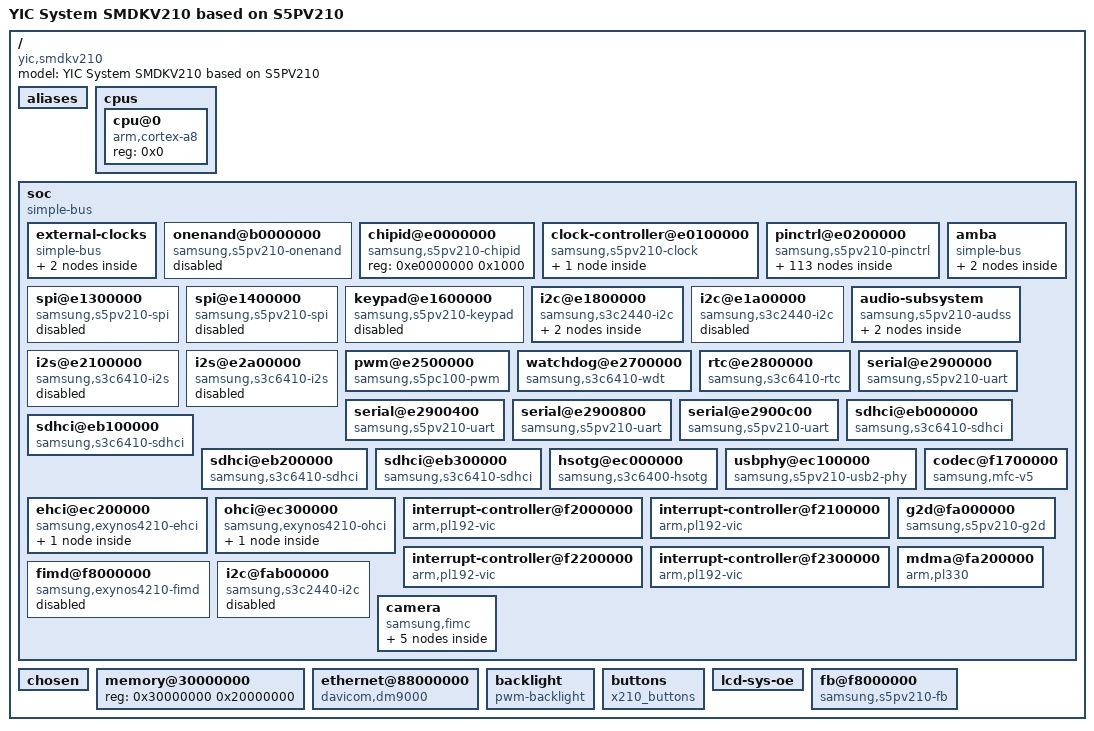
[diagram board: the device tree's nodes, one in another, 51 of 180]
/dts-v1/;

/ {
	#address-cells = <0x1>;
	#size-cells = <0x1>;
	model = "YIC System SMDKV210 based on S5PV210";
	compatible = "yic,smdkv210", "samsung,s5pv210";

	aliases {
		csis0 = "/soc/camera/csis@fa600000";
		fimc0 = "/soc/camera/fimc@fb200000";
		fimc1 = "/soc/camera/fimc@fb300000";
		fimc2 = "/soc/camera/fimc@fb400000";
		i2c0 = "/soc/i2c@e1800000";
		i2c1 = "/soc/i2c@fab00000";
		i2c2 = "/soc/i2c@e1a00000";
		i2s0 = "/soc/audio-subsystem/i2s@eee30000";
		i2s1 = "/soc/i2s@e2100000";
		i2s2 = "/soc/i2s@e2a00000";
		pinctrl0 = "/soc/pinctrl@e0200000";
		spi0 = "/soc/spi@e1300000";
		spi1 = "/soc/spi@e1400000";
	};

	cpus {
		#address-cells = <0x1>;
		#size-cells = <0x0>;

		cpu@0 {
			device_type = "cpu";
			compatible = "arm,cortex-a8";
			reg = <0x0>;
		};
	};

	soc {
		compatible = "simple-bus";
		#address-cells = <0x1>;
		#size-cells = <0x1>;
		ranges;

		external-clocks {
			compatible = "simple-bus";
			#address-cells = <0x1>;
			#size-cells = <0x0>;

			oscillator@0 {
				compatible = "fixed-clock";
				reg = <0x0>;
				clock-frequency = <0x0>;
				clock-output-names = "xxti";
				#clock-cells = <0x0>;
				phandle = <0x3>;
			};

			oscillator@1 {
				compatible = "fixed-clock";
				reg = <0x1>;
				clock-frequency = <0x16e3600>;
				clock-output-names = "xusbxti";
				#clock-cells = <0x0>;
				phandle = <0x4>;
			};
		};

		onenand@b0000000 {
			compatible = "samsung,s5pv210-onenand";
			reg = <0xb0600000 0x2000 0xb0000000 0x20000 0xb0040000 0x20000>;
			interrupt-parent = <0x1>;
			interrupts = <0x1f>;
			clocks = <0x2 0x68 0x2 0x50>;
			clock-names = "bus", "onenand";
			#address-cells = <0x1>;
			#size-cells = <0x1>;
			status = "disabled";
		};

		chipid@e0000000 {
			compatible = "samsung,s5pv210-chipid";
			reg = <0xe0000000 0x1000>;
		};

		clock-controller@e0100000 {
			compatible = "samsung,s5pv210-clock", "simple-bus";
			reg = <0xe0100000 0x10000>;
			clock-names = "xxti", "xusbxti";
			clocks = <0x3 0x4>;
			#clock-cells = <0x1>;
			#address-cells = <0x1>;
			#size-cells = <0x1>;
			ranges;
			phandle = <0x2>;

			syscon@e0108000 {
				compatible = "samsung-s5pv210-pmu", "syscon";
				reg = <0xe0108000 0x8000>;
				phandle = <0x27>;
			};
		};

		pinctrl@e0200000 {
			compatible = "samsung,s5pv210-pinctrl";
			reg = <0xe0200000 0x1000>;
			interrupt-parent = <0x5>;
			interrupts = <0x1e>;

			wakeup-interrupt-controller {
				compatible = "samsung,exynos4210-wakeup-eint";
				interrupts = <0x10>;
				interrupt-parent = <0x5>;
			};

			gpa0 {
				gpio-controller;
				#gpio-cells = <0x2>;
				interrupt-controller;
				#interrupt-cells = <0x2>;
			};

			gpa1 {
				gpio-controller;
				#gpio-cells = <0x2>;
				interrupt-controller;
				#interrupt-cells = <0x2>;
			};

			gpb {
				gpio-controller;
				#gpio-cells = <0x2>;
				interrupt-controller;
				#interrupt-cells = <0x2>;
			};

			gpc0 {
				gpio-controller;
				#gpio-cells = <0x2>;
				interrupt-controller;
				#interrupt-cells = <0x2>;
			};

			gpc1 {
				gpio-controller;
				#gpio-cells = <0x2>;
				interrupt-controller;
				#interrupt-cells = <0x2>;
			};

			gpd0 {
				gpio-controller;
				#gpio-cells = <0x2>;
				interrupt-controller;
				#interrupt-cells = <0x2>;
			};

			gpd1 {
				gpio-controller;
				#gpio-cells = <0x2>;
				interrupt-controller;
				#interrupt-cells = <0x2>;
			};

			gpe0 {
				gpio-controller;
				#gpio-cells = <0x2>;
				interrupt-controller;
				#interrupt-cells = <0x2>;
			};

			gpe1 {
				gpio-controller;
				#gpio-cells = <0x2>;
				interrupt-controller;
				#interrupt-cells = <0x2>;
			};

			gpf0 {
				gpio-controller;
				#gpio-cells = <0x2>;
				interrupt-controller;
				#interrupt-cells = <0x2>;
			};

			gpf1 {
				gpio-controller;
				#gpio-cells = <0x2>;
				interrupt-controller;
				#interrupt-cells = <0x2>;
			};

			gpf2 {
				gpio-controller;
				#gpio-cells = <0x2>;
				interrupt-controller;
				#interrupt-cells = <0x2>;
			};

			gpf3 {
				gpio-controller;
				#gpio-cells = <0x2>;
				interrupt-controller;
				#interrupt-cells = <0x2>;
			};

			gpg0 {
				gpio-controller;
				#gpio-cells = <0x2>;
				interrupt-controller;
				#interrupt-cells = <0x2>;
			};

			gpg1 {
				gpio-controller;
				#gpio-cells = <0x2>;
				interrupt-controller;
				#interrupt-cells = <0x2>;
			};

			gpg2 {
				gpio-controller;
				#gpio-cells = <0x2>;
				interrupt-controller;
				#interrupt-cells = <0x2>;
			};

			gpg3 {
				gpio-controller;
				#gpio-cells = <0x2>;
				interrupt-controller;
				#interrupt-cells = <0x2>;
			};

			gpj0 {
				gpio-controller;
				#gpio-cells = <0x2>;
				interrupt-controller;
				#interrupt-cells = <0x2>;
			};

			gpj1 {
				gpio-controller;
				#gpio-cells = <0x2>;
				interrupt-controller;
				#interrupt-cells = <0x2>;
			};

			gpj2 {
				gpio-controller;
				#gpio-cells = <0x2>;
				interrupt-controller;
				#interrupt-cells = <0x2>;
			};

			gpj3 {
				gpio-controller;
				#gpio-cells = <0x2>;
				interrupt-controller;
				#interrupt-cells = <0x2>;
			};

			gpj4 {
				gpio-controller;
				#gpio-cells = <0x2>;
				interrupt-controller;
				#interrupt-cells = <0x2>;
			};

			gpgi {
				gpio-controller;
				#gpio-cells = <0x2>;
			};

			mp01 {
				gpio-controller;
				#gpio-cells = <0x2>;
			};

			mp02 {
				gpio-controller;
				#gpio-cells = <0x2>;
			};

			mp03 {
				gpio-controller;
				#gpio-cells = <0x2>;
			};

			mp04 {
				gpio-controller;
				#gpio-cells = <0x2>;
			};

			mp05 {
				gpio-controller;
				#gpio-cells = <0x2>;
			};

			mp06 {
				gpio-controller;
				#gpio-cells = <0x2>;
			};

			mp07 {
				gpio-controller;
				#gpio-cells = <0x2>;
			};

			gph0 {
				gpio-controller;
				interrupt-controller;
				interrupt-parent = <0x5>;
				interrupts = <0x0 0x1 0x2 0x3 0x4 0x5 0x6 0x7>;
				#gpio-cells = <0x2>;
				#interrupt-cells = <0x2>;
			};

			gph1 {
				gpio-controller;
				interrupt-controller;
				interrupt-parent = <0x5>;
				interrupts = <0x8 0x9 0xa 0xb 0xc 0xd 0xe 0xf>;
				#gpio-cells = <0x2>;
				#interrupt-cells = <0x2>;
				phandle = <0x29>;
			};

			gph2 {
				gpio-controller;
				#gpio-cells = <0x2>;
				interrupt-controller;
				#interrupt-cells = <0x2>;
				phandle = <0x2c>;
			};

			gph3 {
				gpio-controller;
				#gpio-cells = <0x2>;
				#interrupt-cells = <0x2>;
			};

			uart0-data {
				samsung,pins = "gpa0-0", "gpa0-1";
				samsung,pin-function = <0x2>;
				samsung,pin-pud = <0x0>;
				samsung,pin-drv = <0x0>;
			};

			uart0-fctl {
				samsung,pins = "gpa0-2", "gpa0-3";
				samsung,pin-function = <0x2>;
				samsung,pin-pud = <0x0>;
				samsung,pin-drv = <0x0>;
			};

			uart1-data {
				samsung,pins = "gpa0-4", "gpa0-5";
				samsung,pin-function = <0x2>;
				samsung,pin-pud = <0x0>;
				samsung,pin-drv = <0x0>;
			};

			uart1-fctl {
				samsung,pins = "gpa0-6", "gpa0-7";
				samsung,pin-function = <0x2>;
				samsung,pin-pud = <0x0>;
				samsung,pin-drv = <0x0>;
			};

			uart2-data {
				samsung,pins = "gpa1-0", "gpa1-1";
				samsung,pin-function = <0x2>;
				samsung,pin-pud = <0x0>;
				samsung,pin-drv = <0x0>;
			};

			uart2-fctl {
				samsung,pins = "gpa1-2", "gpa1-3";
				samsung,pin-function = <0x3>;
				samsung,pin-pud = <0x0>;
				samsung,pin-drv = <0x0>;
			};

			uart3-data {
				samsung,pins = "gpa1-2", "gpa1-3";
				samsung,pin-function = <0x2>;
				samsung,pin-pud = <0x0>;
				samsung,pin-drv = <0x0>;
			};

			uart-audio {
				samsung,pins = "gpa1-2", "gpa1-3";
				samsung,pin-function = <0x4>;
				samsung,pin-pud = <0x0>;
				samsung,pin-drv = <0x0>;
			};

			spi0-bus {
				samsung,pins = "gpb-0", "gpb-2", "gpb-3";
				samsung,pin-function = <0x2>;
				samsung,pin-pud = <0x2>;
				samsung,pin-drv = <0x0>;
				phandle = <0x7>;
			};

			spi1-bus {
				samsung,pins = "gpb-4", "gpb-6", "gpb-7";
				samsung,pin-function = <0x2>;
				samsung,pin-pud = <0x2>;
				samsung,pin-drv = <0x0>;
				phandle = <0x9>;
			};

			i2s0-bus {
				samsung,pins = "gpi-0", "gpi-1", "gpi-2", "gpi-3", "gpi-4", "gpi-5", "gpi-6";
				samsung,pin-function = <0x2>;
				samsung,pin-pud = <0x0>;
				samsung,pin-drv = <0x0>;
				phandle = <0xe>;
			};

			i2s1-bus {
				samsung,pins = "gpc0-0", "gpc0-1", "gpc0-2", "gpc0-3", "gpc0-4";
				samsung,pin-function = <0x2>;
				samsung,pin-pud = <0x0>;
				samsung,pin-drv = <0x0>;
				phandle = <0xf>;
			};

			i2s2-bus {
				samsung,pins = "gpc1-0", "gpc1-1", "gpc1-2", "gpc1-3", "gpc1-4";
				samsung,pin-function = <0x2>;
				samsung,pin-pud = <0x0>;
				samsung,pin-drv = <0x0>;
				phandle = <0x10>;
			};

			pcm1-bus {
				samsung,pins = "gpc0-0", "gpc0-1", "gpc0-2", "gpc0-3", "gpc0-4";
				samsung,pin-function = <0x3>;
				samsung,pin-pud = <0x0>;
				samsung,pin-drv = <0x0>;
			};

			ac97-bus {
				samsung,pins = "gpc0-0", "gpc0-1", "gpc0-2", "gpc0-3", "gpc0-4";
				samsung,pin-function = <0x4>;
				samsung,pin-pud = <0x0>;
				samsung,pin-drv = <0x0>;
			};

			pcm2-bus {
				samsung,pins = "gpc1-0", "gpc1-1", "gpc1-2", "gpc1-3", "gpc1-4";
				samsung,pin-function = <0x3>;
				samsung,pin-pud = <0x0>;
				samsung,pin-drv = <0x0>;
			};

			spdif-bus {
				samsung,pins = "gpc1-0", "gpc1-1";
				samsung,pin-function = <0x4>;
				samsung,pin-pud = <0x0>;
				samsung,pin-drv = <0x0>;
			};

			spi2-bus {
				samsung,pins = "gpc1-1", "gpc1-2", "gpc1-3", "gpc1-4";
				samsung,pin-function = <0x5>;
				samsung,pin-pud = <0x2>;
				samsung,pin-drv = <0x0>;
			};

			i2c0-bus {
				samsung,pins = "gpd1-0", "gpd1-1";
				samsung,pin-function = <0x2>;
				samsung,pin-pud = <0x2>;
				samsung,pin-drv = <0x0>;
				phandle = <0xb>;
			};

			i2c1-bus {
				samsung,pins = "gpd1-2", "gpd1-3";
				samsung,pin-function = <0x2>;
				samsung,pin-pud = <0x2>;
				samsung,pin-drv = <0x0>;
				phandle = <0x28>;
			};

			i2c2-bus {
				samsung,pins = "gpd1-4", "gpd1-5";
				samsung,pin-function = <0x2>;
				samsung,pin-pud = <0x2>;
				samsung,pin-drv = <0x0>;
				phandle = <0xc>;
			};

			pwm0-out {
				samsung,pins = "gpd0-0";
				samsung,pin-function = <0x2>;
				samsung,pin-pud = <0x0>;
				samsung,pin-drv = <0x0>;
			};

			pwm1-out {
				samsung,pins = "gpd0-1";
				samsung,pin-function = <0x2>;
				samsung,pin-pud = <0x0>;
				samsung,pin-drv = <0x0>;
			};

			pwm2-out {
				samsung,pins = "gpd0-2";
				samsung,pin-function = <0x2>;
				samsung,pin-pud = <0x0>;
				samsung,pin-drv = <0x0>;
			};

			pwm3-out {
				samsung,pins = "gpd0-3";
				samsung,pin-function = <0x2>;
				samsung,pin-pud = <0x0>;
				samsung,pin-drv = <0x0>;
				phandle = <0x2b>;
			};

			keypad-row-0 {
				samsung,pins = "gph3-0";
				samsung,pin-function = <0x3>;
				samsung,pin-pud = <0x0>;
				samsung,pin-drv = <0x0>;
			};

			keypad-row-1 {
				samsung,pins = "gph3-1";
				samsung,pin-function = <0x3>;
				samsung,pin-pud = <0x0>;
				samsung,pin-drv = <0x0>;
			};

			keypad-row-2 {
				samsung,pins = "gph3-2";
				samsung,pin-function = <0x3>;
				samsung,pin-pud = <0x0>;
				samsung,pin-drv = <0x0>;
			};

			keypad-row-3 {
				samsung,pins = "gph3-3";
				samsung,pin-function = <0x3>;
				samsung,pin-pud = <0x0>;
				samsung,pin-drv = <0x0>;
			};

			keypad-row-4 {
				samsung,pins = "gph3-4";
				samsung,pin-function = <0x3>;
				samsung,pin-pud = <0x0>;
				samsung,pin-drv = <0x0>;
			};

			keypad-row-5 {
				samsung,pins = "gph3-5";
				samsung,pin-function = <0x3>;
				samsung,pin-pud = <0x0>;
				samsung,pin-drv = <0x0>;
			};

			keypad-row-6 {
				samsung,pins = "gph3-6";
				samsung,pin-function = <0x3>;
				samsung,pin-pud = <0x0>;
				samsung,pin-drv = <0x0>;
			};

			keypad-row-7 {
				samsung,pins = "gph3-7";
				samsung,pin-function = <0x3>;
				samsung,pin-pud = <0x0>;
				samsung,pin-drv = <0x0>;
			};

			keypad-col-0 {
				samsung,pins = "gph2-0";
				samsung,pin-function = <0x3>;
				samsung,pin-pud = <0x0>;
				samsung,pin-drv = <0x0>;
			};

			keypad-col-1 {
				samsung,pins = "gph2-1";
				samsung,pin-function = <0x3>;
				samsung,pin-pud = <0x0>;
				samsung,pin-drv = <0x0>;
			};

			keypad-col-2 {
				samsung,pins = "gph2-2";
				samsung,pin-function = <0x3>;
				samsung,pin-pud = <0x0>;
				samsung,pin-drv = <0x0>;
			};

			keypad-col-3 {
				samsung,pins = "gph2-3";
				samsung,pin-function = <0x3>;
				samsung,pin-pud = <0x0>;
				samsung,pin-drv = <0x0>;
			};

			keypad-col-4 {
				samsung,pins = "gph2-4";
				samsung,pin-function = <0x3>;
				samsung,pin-pud = <0x0>;
				samsung,pin-drv = <0x0>;
			};

			keypad-col-5 {
				samsung,pins = "gph2-5";
				samsung,pin-function = <0x3>;
				samsung,pin-pud = <0x0>;
				samsung,pin-drv = <0x0>;
			};

			keypad-col-6 {
				samsung,pins = "gph2-6";
				samsung,pin-function = <0x3>;
				samsung,pin-pud = <0x0>;
				samsung,pin-drv = <0x0>;
			};

			keypad-col-7 {
				samsung,pins = "gph2-7";
				samsung,pin-function = <0x3>;
				samsung,pin-pud = <0x0>;
				samsung,pin-drv = <0x0>;
			};

			sd0-clk {
				samsung,pins = "gpg0-0";
				samsung,pin-function = <0x2>;
				samsung,pin-pud = <0x0>;
				samsung,pin-drv = <0x3>;
				phandle = <0x11>;
			};

			sd0-cmd {
				samsung,pins = "gpg0-1";
				samsung,pin-function = <0x2>;
				samsung,pin-pud = <0x0>;
				samsung,pin-drv = <0x3>;
				phandle = <0x12>;
			};

			sd0-cd {
				samsung,pins = "gpg0-2";
				samsung,pin-function = <0x2>;
				samsung,pin-pud = <0x2>;
				samsung,pin-drv = <0x3>;
				phandle = <0x13>;
			};

			sd0-bus-width1 {
				samsung,pins = "gpg0-3";
				samsung,pin-function = <0x2>;
				samsung,pin-pud = <0x2>;
				samsung,pin-drv = <0x3>;
				phandle = <0x14>;
			};

			sd0-bus-width4 {
				samsung,pins = "gpg0-3", "gpg0-4", "gpg0-5", "gpg0-6";
				samsung,pin-function = <0x2>;
				samsung,pin-pud = <0x2>;
				samsung,pin-drv = <0x3>;
				phandle = <0x15>;
			};

			sd0-bus-width8 {
				samsung,pins = "gpg1-3", "gpg1-4", "gpg1-5", "gpg1-6";
				samsung,pin-function = <0x3>;
				samsung,pin-pud = <0x2>;
				samsung,pin-drv = <0x3>;
			};

			sd1-clk {
				samsung,pins = "gpg1-0";
				samsung,pin-function = <0x2>;
				samsung,pin-pud = <0x0>;
				samsung,pin-drv = <0x3>;
				phandle = <0x16>;
			};

			sd1-cmd {
				samsung,pins = "gpg1-1";
				samsung,pin-function = <0x2>;
				samsung,pin-pud = <0x0>;
				samsung,pin-drv = <0x3>;
				phandle = <0x17>;
			};

			sd1-cd {
				samsung,pins = "gpg1-2";
				samsung,pin-function = <0x2>;
				samsung,pin-pud = <0x2>;
				samsung,pin-drv = <0x3>;
				phandle = <0x18>;
			};

			sd1-bus-width1 {
				samsung,pins = "gpg1-3";
				samsung,pin-function = <0x2>;
				samsung,pin-pud = <0x2>;
				samsung,pin-drv = <0x3>;
				phandle = <0x19>;
			};

			sd1-bus-width4 {
				samsung,pins = "gpg1-3", "gpg1-4", "gpg1-5", "gpg1-6";
				samsung,pin-function = <0x2>;
				samsung,pin-pud = <0x2>;
				samsung,pin-drv = <0x3>;
				phandle = <0x1a>;
			};

			sd2-clk {
				samsung,pins = "gpg2-0";
				samsung,pin-function = <0x2>;
				samsung,pin-pud = <0x0>;
				samsung,pin-drv = <0x3>;
				phandle = <0x1b>;
			};

			sd2-cmd {
				samsung,pins = "gpg2-1";
				samsung,pin-function = <0x2>;
				samsung,pin-pud = <0x0>;
				samsung,pin-drv = <0x3>;
				phandle = <0x1c>;
			};

			sd2-cd {
				samsung,pins = "gpg2-2";
				samsung,pin-function = <0x2>;
				samsung,pin-pud = <0x2>;
				samsung,pin-drv = <0x3>;
				phandle = <0x1d>;
			};

			sd2-bus-width1 {
				samsung,pins = "gpg2-3";
				samsung,pin-function = <0x2>;
				samsung,pin-pud = <0x2>;
				samsung,pin-drv = <0x3>;
				phandle = <0x1e>;
			};

			sd2-bus-width4 {
				samsung,pins = "gpg2-3", "gpg2-4", "gpg2-5", "gpg2-6";
				samsung,pin-function = <0x2>;
				samsung,pin-pud = <0x2>;
				samsung,pin-drv = <0x3>;
				phandle = <0x1f>;
			};

			sd2-bus-width8 {
				samsung,pins = "gpg3-3", "gpg3-4", "gpg3-5", "gpg3-6";
				samsung,pin-function = <0x3>;
				samsung,pin-pud = <0x2>;
				samsung,pin-drv = <0x3>;
			};

			sd3-clk {
				samsung,pins = "gpg3-0";
				samsung,pin-function = <0x2>;
				samsung,pin-pud = <0x0>;
				samsung,pin-drv = <0x3>;
				phandle = <0x21>;
			};

			sd3-cmd {
				samsung,pins = "gpg3-1";
				samsung,pin-function = <0x2>;
				samsung,pin-pud = <0x0>;
				samsung,pin-drv = <0x3>;
				phandle = <0x22>;
			};

			sd3-cd {
				samsung,pins = "gpg3-2";
				samsung,pin-function = <0x2>;
				samsung,pin-pud = <0x2>;
				samsung,pin-drv = <0x3>;
				phandle = <0x23>;
			};

			sd3-bus-width1 {
				samsung,pins = "gpg3-3";
				samsung,pin-function = <0x2>;
				samsung,pin-pud = <0x2>;
				samsung,pin-drv = <0x3>;
				phandle = <0x24>;
			};

			sd3-bus-width4 {
				samsung,pins = "gpg3-3", "gpg3-4", "gpg3-5", "gpg3-6";
				samsung,pin-function = <0x2>;
				samsung,pin-pud = <0x2>;
				samsung,pin-drv = <0x3>;
				phandle = <0x25>;
			};

			ext-int0 {
				samsung,pins = "gph0-0";
				samsung,pin-function = <0xf>;
				samsung,pin-pud = <0x0>;
				samsung,pin-drv = <0x0>;
			};

			ext-int8 {
				samsung,pins = "gph1-0";
				samsung,pin-function = <0xf>;
				samsung,pin-pud = <0x0>;
				samsung,pin-drv = <0x0>;
			};

			ext-int15 {
				samsung,pins = "gph1-7";
				samsung,pin-function = <0xf>;
				samsung,pin-pud = <0x0>;
				samsung,pin-drv = <0x0>;
			};

			ext-int16 {
				samsung,pins = "gph2-0";
				samsung,pin-function = <0xf>;
				samsung,pin-pud = <0x0>;
				samsung,pin-drv = <0x0>;
			};

			ext-int31 {
				samsung,pins = "gph3-7";
				samsung,pin-function = <0xf>;
				samsung,pin-pud = <0x0>;
				samsung,pin-drv = <0x0>;
			};

			cam-port-a-io {
				samsung,pins = "gpe0-0", "gpe0-1", "gpe0-2", "gpe0-3", "gpe0-4", "gpe0-5", "gpe0-6", "gpe0-7", "gpe1-0", "gpe1-1", "gpe1-2", "gpe1-4";
				samsung,pin-function = <0x2>;
				samsung,pin-pud = <0x0>;
				samsung,pin-drv = <0x0>;
			};

			cam-port-a-clk-active {
				samsung,pins = "gpe1-3";
				samsung,pin-function = <0x2>;
				samsung,pin-pud = <0x0>;
				samsung,pin-drv = <0x3>;
			};

			cam-port-a-clk-idle {
				samsung,pins = "gpe1-3";
				samsung,pin-function = <0x0>;
				samsung,pin-pud = <0x1>;
				samsung,pin-drv = <0x0>;
			};

			cam-port-b-io {
				samsung,pins = "gpj0-0", "gpj0-1", "gpj0-2", "gpj0-3", "gpj0-4", "gpj0-5", "gpj0-6", "gpj0-7", "gpj1-0", "gpj1-1", "gpj1-2", "gpj1-4";
				samsung,pin-function = <0x3>;
				samsung,pin-pud = <0x0>;
				samsung,pin-drv = <0x0>;
			};

			cam-port-b-clk-active {
				samsung,pins = "gpj1-3";
				samsung,pin-function = <0x3>;
				samsung,pin-pud = <0x0>;
				samsung,pin-drv = <0x3>;
			};

			cam-port-b-clk-idle {
				samsung,pins = "gpj1-3";
				samsung,pin-function = <0x0>;
				samsung,pin-pud = <0x1>;
				samsung,pin-drv = <0x0>;
			};

			lcd-ctrl {
				samsung,pins = "gpd0-0", "gpd0-1";
				samsung,pin-function = <0x1>;
				samsung,pin-pud = <0x0>;
				samsung,pin-drv = <0x0>;
				samsung,pin-val = <0x0>;
				phandle = <0x2f>;
			};

			lcd-sync {
				samsung,pins = "gpf0-0", "gpf0-1";
				samsung,pin-function = <0x2>;
				samsung,pin-pud = <0x0>;
				samsung,pin-drv = <0x0>;
			};

			lcd-clk {
				samsung,pins = "gpf0-0", "gpf0-1", "gpf0-2", "gpf0-3";
				samsung,pin-function = <0x2>;
				samsung,pin-pud = <0x0>;
				samsung,pin-drv = <0x0>;
				phandle = <0x2e>;
			};

			lcd-data-width24 {
				samsung,pins = "gpf0-4", "gpf0-5", "gpf0-6", "gpf0-7", "gpf1-0", "gpf1-1", "gpf1-2", "gpf1-3", "gpf1-4", "gpf1-5", "gpf1-6", "gpf1-7", "gpf2-0", "gpf2-1", "gpf2-2", "gpf2-3", "gpf2-4", "gpf2-5", "gpf2-6", "gpf2-7", "gpf3-0", "gpf3-1", "gpf3-2", "gpf3-3";
				samsung,pin-function = <0x2>;
				samsung,pin-pud = <0x0>;
				samsung,pin-drv = <0x0>;
				phandle = <0x2d>;
			};
		};

		amba {
			#address-cells = <0x1>;
			#size-cells = <0x1>;
			compatible = "simple-bus";
			ranges;

			dma@e0900000 {
				compatible = "arm,pl330", "arm,primecell";
				reg = <0xe0900000 0x1000>;
				interrupt-parent = <0x5>;
				interrupts = <0x13>;
				clocks = <0x2 0x61>;
				clock-names = "apb_pclk";
				#dma-cells = <0x1>;
				#dma-channels = <0x8>;
				#dma-requests = <0x20>;
				phandle = <0x6>;
			};

			dma@e0a00000 {
				compatible = "arm,pl330", "arm,primecell";
				reg = <0xe0a00000 0x1000>;
				interrupt-parent = <0x5>;
				interrupts = <0x14>;
				clocks = <0x2 0x60>;
				clock-names = "apb_pclk";
				#dma-cells = <0x1>;
				#dma-channels = <0x8>;
				#dma-requests = <0x20>;
				phandle = <0x8>;
			};
		};

		spi@e1300000 {
			compatible = "samsung,s5pv210-spi";
			reg = <0xe1300000 0x1000>;
			interrupt-parent = <0x1>;
			interrupts = <0xf>;
			dmas = <0x6 0x7 0x6 0x6>;
			dma-names = "tx", "rx";
			clocks = <0x2 0xab 0x2 0x93>;
			clock-names = "spi", "spi_busclk0";
			pinctrl-names = "default";
			pinctrl-0 = <0x7>;
			#address-cells = <0x1>;
			#size-cells = <0x0>;
			status = "disabled";
		};

		spi@e1400000 {
			compatible = "samsung,s5pv210-spi";
			reg = <0xe1400000 0x1000>;
			interrupt-parent = <0x1>;
			interrupts = <0x10>;
			dmas = <0x8 0x7 0x8 0x6>;
			dma-names = "tx", "rx";
			clocks = <0x2 0xaa 0x2 0x92>;
			clock-names = "spi", "spi_busclk0";
			pinctrl-names = "default";
			pinctrl-0 = <0x9>;
			#address-cells = <0x1>;
			#size-cells = <0x0>;
			status = "disabled";
		};

		keypad@e1600000 {
			compatible = "samsung,s5pv210-keypad";
			reg = <0xe1600000 0x1000>;
			interrupt-parent = <0xa>;
			interrupts = <0x19>;
			clocks = <0x2 0x8b>;
			clock-names = "keypad";
			status = "disabled";
		};

		i2c@e1800000 {
			compatible = "samsung,s3c2440-i2c";
			reg = <0xe1800000 0x1000>;
			interrupt-parent = <0x1>;
			interrupts = <0xe>;
			clocks = <0x2 0x97>;
			clock-names = "i2c";
			pinctrl-names = "default";
			pinctrl-0 = <0xb>;
			#address-cells = <0x1>;
			#size-cells = <0x0>;
			status = "okay";

			audio-codec@1b {
				compatible = "wlf,wm8580";
				reg = <0x1b>;
			};

			eeprom@50 {
				compatible = "atmel,24c08";
				reg = <0x50>;
			};
		};

		i2c@e1a00000 {
			compatible = "samsung,s3c2440-i2c";
			reg = <0xe1a00000 0x1000>;
			interrupt-parent = <0x1>;
			interrupts = <0x13>;
			clocks = <0x2 0x96>;
			clock-names = "i2c";
			pinctrl-0 = <0xc>;
			pinctrl-names = "default";
			#address-cells = <0x1>;
			#size-cells = <0x0>;
			status = "disabled";
		};

		audio-subsystem {
			compatible = "samsung,s5pv210-audss", "simple-bus";
			#address-cells = <0x1>;
			#size-cells = <0x1>;
			ranges;

			clock-controller@eee10000 {
				compatible = "samsung,s5pv210-audss-clock";
				reg = <0xeee10000 0x1000>;
				clock-names = "hclk", "xxti", "fout_epll", "sclk_audio0";
				clocks = <0x2 0x2f 0x3 0x2 0x4 0x2 0xa8>;
				#clock-cells = <0x1>;
				phandle = <0xd>;
			};

			i2s@eee30000 {
				compatible = "samsung,s5pv210-i2s";
				reg = <0xeee30000 0x1000>;
				interrupt-parent = <0xa>;
				interrupts = <0x10>;
				dma-names = "rx", "tx", "tx-sec";
				dmas = <0x8 0x9 0x8 0xa 0x8 0xb>;
				clock-names = "iis", "i2s_opclk0", "i2s_opclk1";
				clocks = <0xd 0x4 0xd 0x4 0xd 0x2>;
				samsung,idma-addr = <0xc0010000>;
				pinctrl-names = "default";
				pinctrl-0 = <0xe>;
				#sound-dai-cells = <0x0>;
				status = "okay";
			};
		};

		i2s@e2100000 {
			compatible = "samsung,s3c6410-i2s";
			reg = <0xe2100000 0x1000>;
			interrupt-parent = <0xa>;
			interrupts = <0x11>;
			dma-names = "rx", "tx";
			dmas = <0x8 0xc 0x8 0xd>;
			clock-names = "iis", "i2s_opclk0";
			clocks = <0x2 0x98 0x2 0xa7>;
			pinctrl-names = "default";
			pinctrl-0 = <0xf>;
			#sound-dai-cells = <0x0>;
			status = "disabled";
		};

		i2s@e2a00000 {
			compatible = "samsung,s3c6410-i2s";
			reg = <0xe2a00000 0x1000>;
			interrupt-parent = <0xa>;
			interrupts = <0x12>;
			dma-names = "rx", "tx";
			dmas = <0x8 0xe 0x8 0xf>;
			clock-names = "iis", "i2s_opclk0";
			clocks = <0x2 0x99 0x2 0xa6>;
			pinctrl-names = "default";
			pinctrl-0 = <0x10>;
			#sound-dai-cells = <0x0>;
			status = "disabled";
		};

		pwm@e2500000 {
			compatible = "samsung,s5pc100-pwm";
			reg = <0xe2500000 0x1000>;
			interrupt-parent = <0x5>;
			interrupts = <0x15 0x16 0x17 0x18 0x19>;
			clock-names = "timers";
			clocks = <0x2 0x89>;
			#pwm-cells = <0x3>;
			phandle = <0x2a>;
		};

		watchdog@e2700000 {
			compatible = "samsung,s3c6410-wdt";
			reg = <0xe2700000 0x1000>;
			interrupt-parent = <0x5>;
			interrupts = <0x1a>;
			clock-names = "watchdog";
			clocks = <0x2 0x8a>;
		};

		rtc@e2800000 {
			compatible = "samsung,s3c6410-rtc";
			reg = <0xe2800000 0x100>;
			interrupt-parent = <0x5>;
			interrupts = <0x1c 0x1d>;
			clocks = <0x2 0x91>;
			clock-names = "rtc";
			status = "okay";
		};

		serial@e2900000 {
			compatible = "samsung,s5pv210-uart";
			reg = <0xe2900000 0x400>;
			interrupt-parent = <0x1>;
			interrupts = <0xa>;
			clock-names = "uart", "clk_uart_baud0", "clk_uart_baud1";
			clocks = <0x2 0x8f 0x2 0x8f 0x2 0xaf>;
			status = "okay";
		};

		serial@e2900400 {
			compatible = "samsung,s5pv210-uart";
			reg = <0xe2900400 0x400>;
			interrupt-parent = <0x1>;
			interrupts = <0xb>;
			clock-names = "uart", "clk_uart_baud0", "clk_uart_baud1";
			clocks = <0x2 0x8e 0x2 0x8e 0x2 0xae>;
			status = "okay";
		};

		serial@e2900800 {
			compatible = "samsung,s5pv210-uart";
			reg = <0xe2900800 0x400>;
			interrupt-parent = <0x1>;
			interrupts = <0xc>;
			clock-names = "uart", "clk_uart_baud0", "clk_uart_baud1";
			clocks = <0x2 0x8d 0x2 0x8d 0x2 0xad>;
			status = "okay";
		};

		serial@e2900c00 {
			compatible = "samsung,s5pv210-uart";
			reg = <0xe2900c00 0x400>;
			interrupt-parent = <0x1>;
			interrupts = <0xd>;
			clock-names = "uart", "clk_uart_baud0", "clk_uart_baud1";
			clocks = <0x2 0x8c 0x2 0x8c 0x2 0xac>;
			status = "okay";
		};

		sdhci@eb000000 {
			compatible = "samsung,s3c6410-sdhci";
			reg = <0xeb000000 0x100000>;
			interrupt-parent = <0x1>;
			interrupts = <0x1a>;
			clock-names = "hsmmc", "mmc_busclk.0", "mmc_busclk.2";
			clocks = <0x2 0x7d 0x2 0x7d 0x2 0xb3>;
			status = "okay";
			bus-width = <0x4>;
			pinctrl-0 = <0x11 0x12 0x13 0x14 0x15>;
			pinctrl-names = "default";
		};

		sdhci@eb100000 {
			compatible = "samsung,s3c6410-sdhci";
			reg = <0xeb100000 0x100000>;
			interrupt-parent = <0x1>;
			interrupts = <0x1b>;
			clock-names = "hsmmc", "mmc_busclk.0", "mmc_busclk.2";
			clocks = <0x2 0x7c 0x2 0x7c 0x2 0xb2>;
			status = "okay";
			bus-width = <0x4>;
			pinctrl-0 = <0x16 0x17 0x18 0x19 0x1a>;
			pinctrl-names = "default";
		};

		sdhci@eb200000 {
			compatible = "samsung,s3c6410-sdhci";
			reg = <0xeb200000 0x100000>;
			interrupt-parent = <0x1>;
			interrupts = <0x1c>;
			clock-names = "hsmmc", "mmc_busclk.0", "mmc_busclk.2";
			clocks = <0x2 0x7b 0x2 0x7b 0x2 0xb1>;
			status = "okay";
			bus-width = <0x4>;
			pinctrl-0 = <0x1b 0x1c 0x1d 0x1e 0x1f>;
			pinctrl-names = "default";
		};

		sdhci@eb300000 {
			compatible = "samsung,s3c6410-sdhci";
			reg = <0xeb300000 0x100000>;
			interrupt-parent = <0x20>;
			interrupts = <0x2>;
			clock-names = "hsmmc", "mmc_busclk.0", "mmc_busclk.3";
			clocks = <0x2 0x7a 0x2 0x7a 0x2 0xb0>;
			status = "okay";
			bus-width = <0x4>;
			pinctrl-0 = <0x21 0x22 0x23 0x24 0x25>;
			pinctrl-names = "default";
		};

		hsotg@ec000000 {
			compatible = "samsung,s3c6400-hsotg";
			reg = <0xec000000 0x20000>;
			interrupt-parent = <0x1>;
			interrupts = <0x18>;
			clocks = <0x2 0x6a>;
			clock-names = "otg";
			phy-names = "usb2-phy";
			phys = <0x26 0x0>;
			status = "okay";
		};

		usbphy@ec100000 {
			compatible = "samsung,s5pv210-usb2-phy";
			reg = <0xec100000 0x100>;
			samsung,pmureg-phandle = <0x27>;
			clocks = <0x2 0x6a 0x4>;
			clock-names = "phy", "ref";
			#phy-cells = <0x1>;
			status = "okay";
			phandle = <0x26>;
		};

		ehci@ec200000 {
			compatible = "samsung,exynos4210-ehci";
			reg = <0xec200000 0x100>;
			interrupts = <0x17>;
			interrupt-parent = <0x1>;
			clocks = <0x2 0x69>;
			clock-names = "usbhost";
			#address-cells = <0x1>;
			#size-cells = <0x0>;
			status = "okay";

			port@0 {
				reg = <0x0>;
				phys = <0x26 0x1>;
			};
		};

		ohci@ec300000 {
			compatible = "samsung,exynos4210-ohci";
			reg = <0xec300000 0x100>;
			interrupts = <0x17>;
			interrupt-parent = <0x1>;
			clocks = <0x2 0x69>;
			clock-names = "usbhost";
			#address-cells = <0x1>;
			#size-cells = <0x0>;
			status = "okay";

			port@0 {
				reg = <0x0>;
				phys = <0x26 0x1>;
			};
		};

		codec@f1700000 {
			compatible = "samsung,mfc-v5";
			reg = <0xf1700000 0x10000>;
			interrupt-parent = <0xa>;
			interrupts = <0xe>;
			clocks = <0x2 0x3c 0x2 0x5c>;
			clock-names = "sclk_mfc", "mfc";
		};

		interrupt-controller@f2000000 {
			compatible = "arm,pl192-vic";
			interrupt-controller;
			reg = <0xf2000000 0x1000>;
			#interrupt-cells = <0x1>;
			phandle = <0x5>;
		};

		interrupt-controller@f2100000 {
			compatible = "arm,pl192-vic";
			interrupt-controller;
			reg = <0xf2100000 0x1000>;
			#interrupt-cells = <0x1>;
			phandle = <0x1>;
		};

		interrupt-controller@f2200000 {
			compatible = "arm,pl192-vic";
			interrupt-controller;
			reg = <0xf2200000 0x1000>;
			#interrupt-cells = <0x1>;
			phandle = <0xa>;
		};

		interrupt-controller@f2300000 {
			compatible = "arm,pl192-vic";
			interrupt-controller;
			reg = <0xf2300000 0x1000>;
			#interrupt-cells = <0x1>;
			phandle = <0x20>;
		};

		fimd@f8000000 {
			compatible = "samsung,exynos4210-fimd";
			interrupt-parent = <0xa>;
			reg = <0xf8000000 0x20000>;
			interrupt-names = "fifo", "vsync", "lcd_sys";
			interrupts = <0x0 0x1 0x2>;
			clocks = <0x2 0xb6 0x2 0x70>;
			clock-names = "sclk_fimd", "fimd";
			status = "disabled";
		};

		g2d@fa000000 {
			compatible = "samsung,s5pv210-g2d";
			reg = <0xfa000000 0x1000>;
			interrupt-parent = <0xa>;
			interrupts = <0x9>;
			clocks = <0x2 0x3b 0x2 0x5d>;
			clock-names = "sclk_fimg2d", "fimg2d";
		};

		mdma@fa200000 {
			compatible = "arm,pl330", "arm,primecell";
			reg = <0xfa200000 0x1000>;
			interrupt-parent = <0x5>;
			interrupts = <0x12>;
			clocks = <0x2 0x62>;
			clock-names = "apb_pclk";
			#dma-cells = <0x1>;
			#dma-channels = <0x8>;
			#dma-requests = <0x1>;
		};

		i2c@fab00000 {
			compatible = "samsung,s3c2440-i2c";
			reg = <0xfab00000 0x1000>;
			interrupt-parent = <0xa>;
			interrupts = <0xd>;
			clocks = <0x2 0x95>;
			clock-names = "i2c";
			pinctrl-names = "default";
			pinctrl-0 = <0x28>;
			#address-cells = <0x1>;
			#size-cells = <0x0>;
			status = "disabled";
		};

		camera {
			compatible = "samsung,fimc", "simple-bus";
			pinctrl-names = "default";
			pinctrl-0;
			clocks = <0x2 0xb8 0x2 0xb7>;
			clock-names = "sclk_cam0", "sclk_cam1";
			#address-cells = <0x1>;
			#size-cells = <0x1>;
			ranges;

			clock-controller {
				#clock-cells = <0x1>;
			};

			csis@fa600000 {
				compatible = "samsung,s5pv210-csis";
				reg = <0xfa600000 0x4000>;
				interrupt-parent = <0xa>;
				interrupts = <0x1d>;
				clocks = <0x2 0x57 0x2 0xb5>;
				clock-names = "clk_csis", "sclk_csis";
				bus-width = <0x4>;
				status = "disabled";
				#address-cells = <0x1>;
				#size-cells = <0x0>;
			};

			fimc@fb200000 {
				compatible = "samsung,s5pv210-fimc";
				reg = <0xfb200000 0x1000>;
				interrupts = <0x5>;
				interrupt-parent = <0xa>;
				clocks = <0x2 0x5b 0x2 0xbe>;
				clock-names = "fimc", "sclk_fimc";
				samsung,pix-limits = <0x1080 0x2000 0x780 0x1080>;
				samsung,mainscaler-ext;
				samsung,cam-if;
			};

			fimc@fb300000 {
				compatible = "samsung,s5pv210-fimc";
				reg = <0xfb300000 0x1000>;
				interrupt-parent = <0xa>;
				interrupts = <0x6>;
				clocks = <0x2 0x5a 0x2 0xbd>;
				clock-names = "fimc", "sclk_fimc";
				samsung,pix-limits = <0x1080 0x2000 0x780 0x1080>;
				samsung,mainscaler-ext;
				samsung,cam-if;
			};

			fimc@fb400000 {
				compatible = "samsung,s5pv210-fimc";
				reg = <0xfb400000 0x1000>;
				interrupt-parent = <0xa>;
				interrupts = <0x7>;
				clocks = <0x2 0x59 0x2 0xbc>;
				clock-names = "fimc", "sclk_fimc";
				samsung,pix-limits = <0x1080 0x2000 0x780 0x1080>;
				samsung,mainscaler-ext;
				samsung,lcd-wb;
			};
		};
	};

	chosen {
		bootargs = "console=ttySAC2,115200n8 root=/dev/nfs nfsroot=192.168.0.101:/home/run/work/rootfs/rootfs_3.16.57 ip=192.1    68.0.20 init=/linuxrci earlyprintk";
	};

	memory@30000000 {
		device_type = "memory";
		reg = <0x30000000 0x20000000>;
	};

	ethernet@88000000 {
		compatible = "davicom,dm9000";
		reg = <0x88000000 0x2 0x88000004 0x2>;
		interrupt-parent = <0x29>;
		interrupts = <0x2 0x4>;
		local-mac-address = [00 00 de ad be ef];
		davicom,no-eeprom;
		clocks = <0x2 0x66>;
		clock-names = "sromc";
	};

	backlight {
		compatible = "pwm-backlight";
		pwms = <0x2a 0x0 0x4c4b40 0x0>;
		brightness-levels = <0x0 0x4 0x8 0x10 0x20 0x40 0x80 0xff>;
		default-brightness-level = <0x6>;
		pinctrl-names = "default";
		pinctrl-0 = <0x2b>;
	};

	buttons {
		compatible = "x210_buttons";
		interrupt-parent = <0x2c>;
		interrupts = <0x0 0x3>;
		eint-pin = <0x2c 0x0 0x0>;
	};

	lcd-sys-oe {
		samsung,pins = "gpf3-5";
		samsung,pin-function = <0x3>;
		samsung,pin-pud = <0x0>;
		samsung,pin-drv = <0x0>;
		phandle = <0x30>;
	};

	fb@f8000000 {
		compatible = "samsung,s5pv210-fb";
		interrupt-parent = <0xa>;
		reg = <0xf8000000 0x20000>;
		interrupt-names = "fifo", "vsync", "lcd_sys";
		interrupts = <0x0 0x1 0x2>;
		clocks = <0x2 0xb6 0x2 0x70>;
		clock-names = "sclk_fimd", "fimd";
		status = "okay";
		pinctrl-0 = <0x2d 0x2e 0x2f 0x30>;
		pinctrl-names = "default";
		clock-frequency = <0x31b13d8>;
		xres = [04 00];
		yres = [02 58];
		max_bpp = [00 20];
		default_bpp = [00 18];
		right_margin = <0xa0>;
		left_margin = <0x8c>;
		hsync-len = <0x14>;
		upper_margin = <0x14>;
		lower_margin = <0xc>;
		vsync-len = <0x3>;
		hsync-active = <0x1>;
		vsync-active = <0x1>;
		de-active = <0x0>;
		pixelclk-active = <0x1>;
		vidout = <0x0>;
		pnrmode = <0x0>;
	};
};
